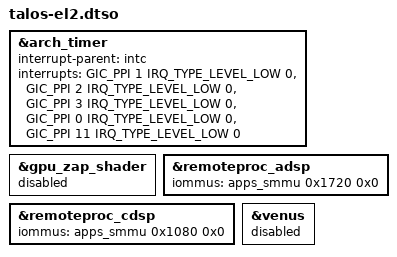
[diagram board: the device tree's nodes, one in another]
// SPDX-License-Identifier: BSD-3-Clause
/*
 * Copyright (c) Qualcomm Technologies, Inc. and/or its subsidiaries.

 * Talos specific modifications required to boot in EL2.
 */

/dts-v1/;
/plugin/;

#include <dt-bindings/interrupt-controller/arm-gic.h>

&arch_timer {
	interrupt-parent = <&intc>;
	interrupts = <GIC_PPI 1 IRQ_TYPE_LEVEL_LOW 0>,
		     <GIC_PPI 2 IRQ_TYPE_LEVEL_LOW 0>,
		     <GIC_PPI 3 IRQ_TYPE_LEVEL_LOW 0>,
		     <GIC_PPI 0 IRQ_TYPE_LEVEL_LOW 0>,
		     <GIC_PPI 11 IRQ_TYPE_LEVEL_LOW 0>;
};

&gpu_zap_shader {
	status = "disabled";
};

&remoteproc_adsp {
	iommus = <&apps_smmu 0x1720 0x0>;
};

&remoteproc_cdsp {
	iommus = <&apps_smmu 0x1080 0x0>;
};

&venus {
	status = "disabled";
};
